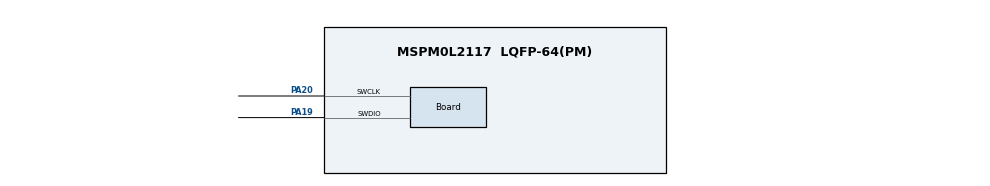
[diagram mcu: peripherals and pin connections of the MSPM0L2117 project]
//@cliArgs --device "MSPM0L211X" --package "LQFP-64(PM)" --part "Default"
//@v2CliArgs --device "MSPM0L2117" --package "LQFP-64(PM)"
// @cliArgs --board /ti/boards/LP_MSPM0L2117 --rtos nortos

/**
 * Import the modules used in this configuration.
 */
const LCD           = scripting.addModule("/ti/driverlib/LCD");
const ProjectConfig = scripting.addModule("/ti/project_config/ProjectConfig");

/**
 * Write custom configuration values to the imported modules.
 */
LCD.freqDiv                                     = 4;
LCD.biasVSource                                 = "AVDD";
LCD.pumpFreq                                    = "1024HZ";
LCD.biasEnable                                  = true;
LCD.vlcdSource                                  = "INTERNAL";
LCD.associatedCOM.create(4);
LCD.associatedCOM[0].$name                      = "LCD_COM_0";
LCD.associatedCOM[0].peripheral.$assign         = "LCD";
LCD.associatedCOM[0].peripheral.LCDCom.$assign  = "PB4";
LCD.associatedCOM[1].$name                      = "LCD_COM_1";
LCD.associatedCOM[1].peripheral.$assign         = "LCD";
LCD.associatedCOM[1].peripheral.LCDCom.$assign  = "PB5";
LCD.associatedCOM[2].$name                      = "LCD_COM_2";
LCD.associatedCOM[2].peripheral.$assign         = "LCD";
LCD.associatedCOM[2].peripheral.LCDCom.$assign  = "PB9";
LCD.associatedCOM[3].$name                      = "LCD_COM_3";
LCD.associatedCOM[3].peripheral.$assign         = "LCD";
LCD.associatedCOM[3].peripheral.LCDCom.$assign  = "PB10";
LCD.associatedSEG.create(24);
LCD.associatedSEG[0].$name                      = "LCD_SEGMENT_LINE_36";
LCD.associatedSEG[0].peripheral.$assign         = "LCD";
LCD.associatedSEG[0].peripheral.LCDSeg.$assign  = "PB11";
LCD.associatedSEG[1].$name                      = "LCD_SEGMENT_LINE_37";
LCD.associatedSEG[1].peripheral.$assign         = "LCD";
LCD.associatedSEG[1].peripheral.LCDSeg.$assign  = "PB12";
LCD.associatedSEG[2].$name                      = "LCD_SEGMENT_LINE_38";
LCD.associatedSEG[2].peripheral.$assign         = "LCD";
LCD.associatedSEG[2].peripheral.LCDSeg.$assign  = "PB13";
LCD.associatedSEG[3].$name                      = "LCD_SEGMENT_LINE_18";
LCD.associatedSEG[3].peripheral.$assign         = "LCD";
LCD.associatedSEG[3].peripheral.LCDSeg.$assign  = "PB17";
LCD.associatedSEG[4].$name                      = "LCD_SEGMENT_LINE_26";
LCD.associatedSEG[4].peripheral.$assign         = "LCD";
LCD.associatedSEG[4].peripheral.LCDSeg.$assign  = "PA24";
LCD.associatedSEG[5].$name                      = "LCD_SEGMENT_LINE_27";
LCD.associatedSEG[5].peripheral.$assign         = "LCD";
LCD.associatedSEG[5].peripheral.LCDSeg.$assign  = "PA25";
LCD.associatedSEG[6].$name                      = "LCD_SEGMENT_LINE_28";
LCD.associatedSEG[6].peripheral.$assign         = "LCD";
LCD.associatedSEG[6].peripheral.LCDSeg.$assign  = "PA26";
LCD.associatedSEG[7].$name                      = "LCD_SEGMENT_LINE_29";
LCD.associatedSEG[7].peripheral.$assign         = "LCD";
LCD.associatedSEG[7].peripheral.LCDSeg.$assign  = "PA27";
LCD.associatedSEG[8].$name                      = "LCD_SEGMENT_LINE_30";
LCD.associatedSEG[8].peripheral.$assign         = "LCD";
LCD.associatedSEG[8].peripheral.LCDSeg.$assign  = "PA28";
LCD.associatedSEG[9].$name                      = "LCD_SEGMENT_LINE_48";
LCD.associatedSEG[9].peripheral.$assign         = "LCD";
LCD.associatedSEG[9].peripheral.LCDSeg.$assign  = "PB3";
LCD.associatedSEG[10].$name                     = "LCD_SEGMENT_LINE_47";
LCD.associatedSEG[10].peripheral.$assign        = "LCD";
LCD.associatedSEG[10].peripheral.LCDSeg.$assign = "PB2";
LCD.associatedSEG[11].$name                     = "LCD_SEGMENT_LINE_45";
LCD.associatedSEG[11].peripheral.$assign        = "LCD";
LCD.associatedSEG[11].peripheral.LCDSeg.$assign = "PA31";
LCD.associatedSEG[12].$name                     = "LCD_SEGMENT_LINE_31";
LCD.associatedSEG[12].peripheral.$assign        = "LCD";
LCD.associatedSEG[12].peripheral.LCDSeg.$assign = "PA29";
LCD.associatedSEG[13].$name                     = "LCD_SEGMENT_LINE_32";
LCD.associatedSEG[13].peripheral.$assign        = "LCD";
LCD.associatedSEG[13].peripheral.LCDSeg.$assign = "PA30";
LCD.associatedSEG[14].$name                     = "LCD_SEGMENT_LINE_19";
LCD.associatedSEG[14].peripheral.$assign        = "LCD";
LCD.associatedSEG[14].peripheral.LCDSeg.$assign = "PB18";
LCD.associatedSEG[15].$name                     = "LCD_SEGMENT_LINE_20";
LCD.associatedSEG[15].peripheral.$assign        = "LCD";
LCD.associatedSEG[15].peripheral.LCDSeg.$assign = "PB19";
LCD.associatedSEG[16].$name                     = "LCD_SEGMENT_LINE_23";
LCD.associatedSEG[16].peripheral.$assign        = "LCD";
LCD.associatedSEG[16].peripheral.LCDSeg.$assign = "PB20";
LCD.associatedSEG[17].$name                     = "LCD_SEGMENT_LINE_39";
LCD.associatedSEG[17].peripheral.$assign        = "LCD";
LCD.associatedSEG[17].peripheral.LCDSeg.$assign = "PB21";
LCD.associatedSEG[18].$name                     = "LCD_SEGMENT_LINE_40";
LCD.associatedSEG[18].peripheral.$assign        = "LCD";
LCD.associatedSEG[18].peripheral.LCDSeg.$assign = "PB22";
LCD.associatedSEG[19].$name                     = "LCD_SEGMENT_LINE_41";
LCD.associatedSEG[19].peripheral.$assign        = "LCD";
LCD.associatedSEG[19].peripheral.LCDSeg.$assign = "PB23";
LCD.associatedSEG[20].$name                     = "LCD_SEGMENT_LINE_24";
LCD.associatedSEG[20].peripheral.$assign        = "LCD";
LCD.associatedSEG[20].peripheral.LCDSeg.$assign = "PB24";
LCD.associatedSEG[21].$name                     = "LCD_SEGMENT_LINE_42";
LCD.associatedSEG[21].peripheral.$assign        = "LCD";
LCD.associatedSEG[21].peripheral.LCDSeg.$assign = "PB25";
LCD.associatedSEG[22].$name                     = "LCD_SEGMENT_LINE_43";
LCD.associatedSEG[22].peripheral.$assign        = "LCD";
LCD.associatedSEG[22].peripheral.LCDSeg.$assign = "PB26";
LCD.associatedSEG[23].$name                     = "LCD_SEGMENT_LINE_44";
LCD.associatedSEG[23].peripheral.$assign        = "LCD";
LCD.associatedSEG[23].peripheral.LCDSeg.$assign = "PB27";
LCD.peripheral.$assign                          = "LCD";

const Board                       = scripting.addModule("/ti/driverlib/Board", {}, false);
Board.peripheral.$assign          = "DEBUGSS";
Board.peripheral.swclkPin.$assign = "PA20";
Board.peripheral.swdioPin.$assign = "PA19";

const SYSCTL              = scripting.addModule("/ti/driverlib/SYSCTL", {}, false);
SYSCTL.peripheral.$assign = "SYSCTL";

ProjectConfig.migrationCondition = true;
